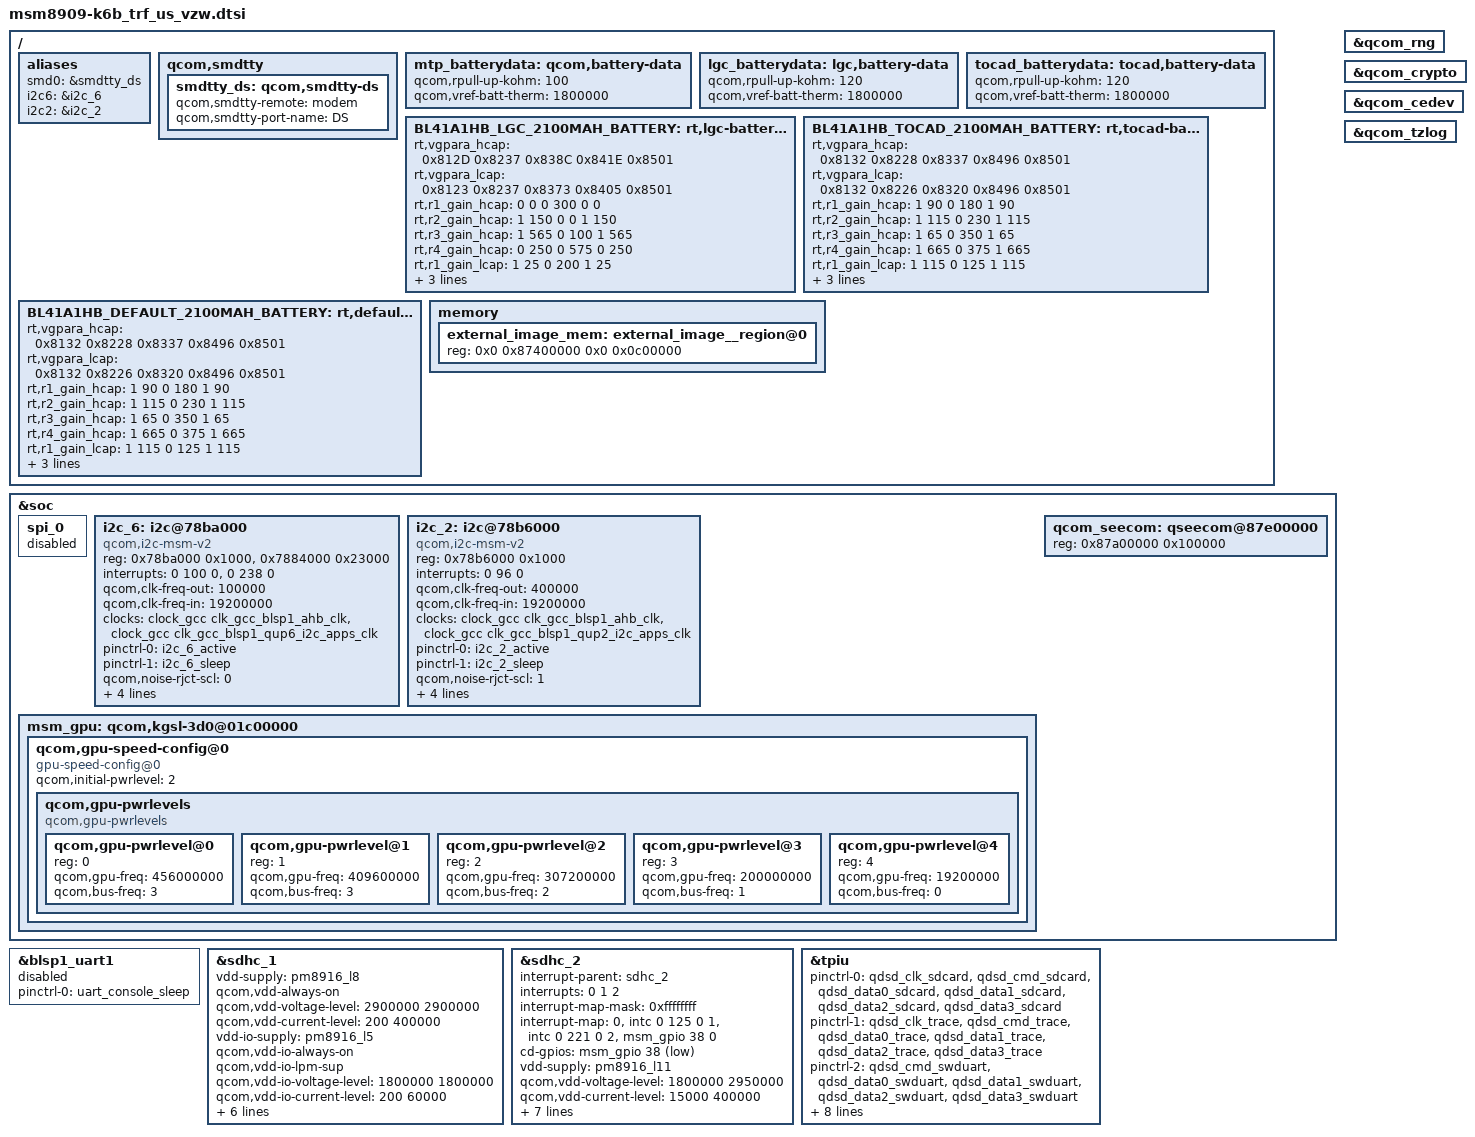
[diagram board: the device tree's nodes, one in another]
/* Copyright (c) 2014, The Linux Foundation. All rights reserved.
 *
 * This program is free software; you can redistribute it and/or modify
 * it under the terms of the GNU General Public License version 2 and
 * only version 2 as published by the Free Software Foundation.
 *
 * This program is distributed in the hope that it will be useful,
 * but WITHOUT ANY WARRANTY; without even the implied warranty of
 * MERCHANTABILITY or FITNESS FOR A PARTICULAR PURPOSE.  See the
 * GNU General Public License for more details.
 */

#include "../../qcom/msm8909.dtsi"
#include "../../qcom/msm8909-pinctrl.dtsi"
#include "../../qcom/msm8909-memory.dtsi"
#include "../msm8909-lge-common/msm8909-common.dtsi"
#include "../msm8909-lge-common/msm8909-e1m1m2m1v-common.dtsi"
#include "msm8909-k6b_trf_us_vzw-pinctrl.dtsi"
#include "msm8909-k6b_trf_us_vzw-sensor.dtsi"

/ {
	aliases {
		smd0 = &smdtty_ds;
		i2c6 = &i2c_6; /* I2c6 cntroller device */
        i2c2 = &i2c_2; /* I2C2 NFC qup2 device */
	};

	qcom,smdtty {
		smdtty_ds: qcom,smdtty-ds {
			qcom,smdtty-remote = "modem";
			qcom,smdtty-port-name = "DS";
		};
	};
};

&soc {
	spi_0 {
		status = "disabled";
	};

	i2c_6: i2c@78ba000 { /* BLSP1 QUP6 */
		compatible = "qcom,i2c-msm-v2";
		#address-cells = <1>;
		#size-cells = <0>;
		reg-names = "qup_phys_addr", "bam_phys_addr";
		reg = <0x78ba000 0x1000>,
		      <0x7884000 0x23000>;
		interrupt-names = "qup_irq", "bam_irq";
		interrupts = <0 100 0>, <0 238 0>;
		qcom,clk-freq-out = <100000>;
		qcom,clk-freq-in  = <19200000>;
		clock-names = "iface_clk", "core_clk";
		clocks = <&clock_gcc clk_gcc_blsp1_ahb_clk>,
			 <&clock_gcc clk_gcc_blsp1_qup6_i2c_apps_clk>;

		pinctrl-names = "i2c_active", "i2c_sleep";
		pinctrl-0 = <&i2c_6_active>;
		pinctrl-1 = <&i2c_6_sleep>;
		qcom,noise-rjct-scl = <0>;
		qcom,noise-rjct-sda = <0>;
		qcom,bam-pipe-idx-cons = <14>;
		qcom,bam-pipe-idx-prod = <15>;
        qcom,master-id = <86>;
    };

    i2c_2: i2c@78b6000 { /* BLSP1 QUP2 */
        compatible = "qcom,i2c-msm-v2";
        #address-cells = <1>;
        #size-cells = <0>;
        reg-names = "qup_phys_addr";
        reg = <0x78b6000 0x1000>;
        interrupt-names = "qup_irq";
        interrupts = <0 96 0>;
        qcom,clk-freq-out = <400000>;
        qcom,clk-freq-in  = <19200000>;
        clock-names = "iface_clk", "core_clk";
        clocks = <&clock_gcc clk_gcc_blsp1_ahb_clk>,
             <&clock_gcc clk_gcc_blsp1_qup2_i2c_apps_clk>;

        pinctrl-names = "i2c_active", "i2c_sleep";
        pinctrl-0 = <&i2c_2_active>;
        pinctrl-1 = <&i2c_2_sleep>;
        qcom,noise-rjct-scl = <1>;
        qcom,noise-rjct-sda = <1>;
        dmas = <&dma_blsp1 6 64 0x20000020 0x20>,
            <&dma_blsp1 7 32 0x20000020 0x20>;
        dma-names = "tx", "rx";
		qcom,master-id = <86>;
	};
	msm_gpu: qcom,kgsl-3d0@01c00000 {
		qcom,gpu-speed-config@0 {
			qcom,initial-pwrlevel = <2>;
			compatible = "gpu-speed-config@0";
			/* Power levels */
			qcom,gpu-pwrlevels {
				#address-cells = <1>;
				#size-cells = <0>;
				compatible = "qcom,gpu-pwrlevels";
				qcom,gpu-pwrlevel@0 {
					reg = <0>;
					qcom,gpu-freq = <456000000>;
					qcom,bus-freq = <3>;
				};

				qcom,gpu-pwrlevel@1 {
					reg = <1>;
					qcom,gpu-freq = <409600000>;
					qcom,bus-freq = <3>;
				};

				qcom,gpu-pwrlevel@2 {
					reg = <2>;
					qcom,gpu-freq = <307200000>;
					qcom,bus-freq = <2>;
				};

				qcom,gpu-pwrlevel@3 {
					reg = <3>;
					qcom,gpu-freq = <200000000>;
					qcom,bus-freq = <1>;
				};

				qcom,gpu-pwrlevel@4 {
					reg = <4>;
					qcom,gpu-freq = <19200000>;
					qcom,bus-freq = <0>;
				};
			};

		};
	};
};

&blsp1_uart1 {
	status = "disabled";
	pinctrl-names = "default";
	pinctrl-0 = <&uart_console_sleep>;
};

/ {
	mtp_batterydata: qcom,battery-data {
		qcom,rpull-up-kohm = <100>;
		qcom,vref-batt-therm = <1800000>;

		#include "../../qcom/batterydata-palladium.dtsi"
	};
};

/ {
	lgc_batterydata: lgc,battery-data {
		qcom,rpull-up-kohm = <120>;
		qcom,vref-batt-therm = <1800000>;

		#include "../msm8909-lge-common/batterydata_LGE_lgc_2100mAh.dtsi"
	};
};

/ {
	tocad_batterydata: tocad,battery-data {
		qcom,rpull-up-kohm = <120>;
		qcom,vref-batt-therm = <1800000>;

		#include "../msm8909-lge-common/batterydata_LGE_tocad_2100mAh.dtsi"
	};
};

/ {
	BL41A1HB_LGC_2100MAH_BATTERY: rt,lgc-battery-data {
		rt,vgpara_hcap = <0x812D 0x8237 0x838C 0x841E 0x8501>;
		rt,vgpara_lcap = <0x8123 0x8237 0x8373 0x8405 0x8501>;
		rt,r1_gain_hcap = < 0 0 0 300 0 0>;
		rt,r2_gain_hcap = < 1 150 0 0 1 150>;
		rt,r3_gain_hcap = < 1 565 0 100 1 565>;
		rt,r4_gain_hcap = < 0 250 0 575 0 250>;
		rt,r1_gain_lcap = < 1 25 0 200 1 25>;
		rt,r2_gain_lcap = < 1 150 0 0 1 150>;
		rt,r3_gain_lcap = < 1 500 0 75 1 500>;
		rt,r4_gain_lcap = < 0 375 0 625 0 375>;

	};

	BL41A1HB_TOCAD_2100MAH_BATTERY: rt,tocad-battery-data {
		rt,vgpara_hcap = <0x8132 0x8228 0x8337 0x8496 0x8501>;
		rt,vgpara_lcap = <0x8132 0x8226 0x8320 0x8496 0x8501>;
		rt,r1_gain_hcap = < 1 90 0 180 1 90>;
		rt,r2_gain_hcap = < 1 115 0 230 1 115>;
		rt,r3_gain_hcap = < 1 65 0 350 1 65>;
		rt,r4_gain_hcap = < 1 665 0 375 1 665>;
		rt,r1_gain_lcap = < 1 115 0 125 1 115>;
		rt,r2_gain_lcap = < 1 105 0 185 1 105>;
		rt,r3_gain_lcap = < 1 25 0 340 1 25>;
		rt,r4_gain_lcap = < 1 665 0 375 1 665>;
	};

	BL41A1HB_DEFAULT_2100MAH_BATTERY: rt,default-battery-data {
		rt,vgpara_hcap = <0x8132 0x8228 0x8337 0x8496 0x8501>;
		rt,vgpara_lcap = <0x8132 0x8226 0x8320 0x8496 0x8501>;
		rt,r1_gain_hcap = < 1 90 0 180 1 90>;
		rt,r2_gain_hcap = < 1 115 0 230 1 115>;
		rt,r3_gain_hcap = < 1 65 0 350 1 65>;
		rt,r4_gain_hcap = < 1 665 0 375 1 665>;
		rt,r1_gain_lcap = < 1 115 0 125 1 115>;
		rt,r2_gain_lcap = < 1 105 0 185 1 105>;
		rt,r3_gain_lcap = < 1 25 0 340 1 25>;
		rt,r4_gain_lcap = < 1 665 0 375 1 665>;
	};
};

&qcom_rng {
	status = "okay";
};

&qcom_crypto {
	status = "okay";
};

&qcom_cedev {
	status = "okay";
};

&qcom_seecom {
	status = "okay";
};

&qcom_tzlog {
	status = "okay";
};

&sdhc_1 {
	vdd-supply = <&pm8916_l8>;
	qcom,vdd-always-on;
	qcom,vdd-voltage-level = <2900000 2900000>;
	qcom,vdd-current-level = <200 400000>;

	vdd-io-supply = <&pm8916_l5>;
	qcom,vdd-io-always-on;
	qcom,vdd-io-lpm-sup;
	qcom,vdd-io-voltage-level = <1800000 1800000>;
	qcom,vdd-io-current-level = <200 60000>;

	pinctrl-names = "active", "sleep";
	pinctrl-0 = <&sdc1_clk_on &sdc1_cmd_on &sdc1_data_on>;
	pinctrl-1 = <&sdc1_clk_off &sdc1_cmd_off &sdc1_data_off>;

	qcom,bus-speed-mode = "HS200_1p8v", "DDR_1p8v";
	qcom,nonremovable;

	status = "ok";
};

&sdhc_2 {
	 #address-cells = <0>;
	interrupt-parent = <&sdhc_2>;
	interrupts = <0 1 2>;
	#interrupt-cells = <1>;
	interrupt-map-mask = <0xffffffff>;
	interrupt-map = <0 &intc 0 125 0
			1 &intc 0 221 0
			2 &msm_gpio 38 0>;
	interrupt-names = "hc_irq", "pwr_irq", "status_irq";
	cd-gpios = <&msm_gpio 38 0x1>;

	vdd-supply = <&pm8916_l11>;
	qcom,vdd-voltage-level = <1800000 2950000>;
	qcom,vdd-current-level = <15000 400000>;

	vdd-io-supply = <&pm8916_l12>;
	qcom,vdd-io-voltage-level = <1800000 2950000>;
	qcom,vdd-io-current-level = <200 50000>;

	pinctrl-names = "active", "sleep";
	pinctrl-0 = <&sdc2_clk_on &sdc2_cmd_on &sdc2_data_on &sdc2_cd_on>;
	pinctrl-1 = <&sdc2_clk_off &sdc2_cmd_off &sdc2_data_off &sdc2_cd_off>;

	status = "ok";
};

/* CoreSight */
&tpiu {
	pinctrl-names = "sdcard", "trace", "swduart",
			"swdtrc", "jtag", "spmi";
	/* NIDnT */
	pinctrl-0 = <&qdsd_clk_sdcard &qdsd_cmd_sdcard
		     &qdsd_data0_sdcard &qdsd_data1_sdcard
		     &qdsd_data2_sdcard &qdsd_data3_sdcard>;
	pinctrl-1 = <&qdsd_clk_trace &qdsd_cmd_trace
		     &qdsd_data0_trace &qdsd_data1_trace
		     &qdsd_data2_trace &qdsd_data3_trace>;
	pinctrl-2 = <&qdsd_cmd_swduart &qdsd_data0_swduart
		     &qdsd_data1_swduart &qdsd_data2_swduart
		     &qdsd_data3_swduart>;
	pinctrl-3 = <&qdsd_clk_swdtrc &qdsd_cmd_swdtrc
		     &qdsd_data0_swdtrc &qdsd_data1_swdtrc
		     &qdsd_data2_swdtrc &qdsd_data3_swdtrc>;
	pinctrl-4 = <&qdsd_cmd_jtag &qdsd_data0_jtag
		     &qdsd_data1_jtag &qdsd_data2_jtag
		     &qdsd_data3_jtag>;
	pinctrl-5 = <&qdsd_clk_spmi &qdsd_cmd_spmi
		     &qdsd_data0_spmi &qdsd_data3_spmi>;
};

/* combine crash handler's disp-buffer & external_image_mem */
/{
	memory {
		external_image_mem: external_image__region@0 {
                    reg = <0x0 0x87400000 0x0 0x0c00000>;
            };
    };
};

&soc {
        qcom_seecom: qseecom@87e00000 {
                reg = <0x87a00000 0x100000>;
        };
};

#include "msm8909-k6b_trf_us_vzw-pm.dtsi"
#include "msm8909-k6b_trf_us_vzw-usb.dtsi"
#include "msm8909-k6b_trf_us_vzw-misc.dtsi"
#include "msm8909-k6b_trf_us_vzw-sound.dtsi"
#include "msm8909-k6b_trf_us_vzw-camera.dtsi"
#include "msm8909-k6b_trf_us_vzw-panel.dtsi"
#include "msm8909-k6b_trf_us_vzw-nfc.dtsi"
